AUTOSAR XML (schema 4-2-1)
package /RootP_STUB_BSWM_CORE1_AppASILA
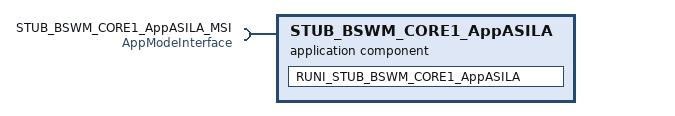
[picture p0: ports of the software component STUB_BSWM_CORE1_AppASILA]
  application sw component type STUB_BSWM_CORE1_AppASILA
    require port STUB_BSWM_CORE1_AppASILA_MSI: required-interface=AppModeInterface
    behavior IB_STUB_BSWM_CORE1_AppASILA: data-type-mapping=ApplicationModeMapping, handle-termination-and-restart=NO-SUPPORT
      swc mode switch event RUNI_STUB_BSWM_CORE1_AppASILA_ENTRY: start-on-event=RUNI_STUB_BSWM_CORE1_AppASILA, activation=ON-ENTRY, mode=STUB_BSWM_CORE1_AppASILA_MSI.AppMode.APP_SYNC_INIT2
      runnable RUNI_STUB_BSWM_CORE1_AppASILA
package /RootP_Implementatation
  swc implementation Implementatation_STUB_BSWM_CORE1_AppASILA: programming-language=C, sw-version=1.0.0, vendor-id=1, behavior=IB_STUB_BSWM_CORE1_AppASILA
    code-descriptors:
      code SRC: artifact-descriptors=autosar-engineering-object={short-label=EngObject, category=SWSRC}
    resource consumption Resources
      memory section CODE: sw-addrmethod=CODE_STUB_BSWM_CORE1_AppASILA
  sw addr method CODE_STUB_BSWM_CORE1_AppASILA: memory-allocation-keyword-policy=ADDR-METHOD-SHORT-NAME-AND-ALIGNMENT, section-type=CODE
